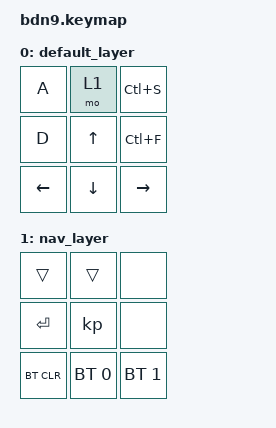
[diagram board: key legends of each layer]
#include <behaviors.dtsi>
#include <dt-bindings/zmk/bt.h>
#include <dt-bindings/zmk/keys.h>
#include <dt-bindings/zmk/outputs.h>
#include <dt-bindings/zmk/ext_power.h>

/ {
    keymap {
        compatible = "zmk,keymap";
        
        default_layer {

            bindings = <
    &kp A &mo 1  &kp LC(S)
    &kp D &kp UP  &kp LC(F)
    &kp LEFT &kp DOWN &kp RIGHT
            >;

            sensor-bindings = <&inc_dec_kp C_VOL_UP C_VOL_DN>;
        };

         nav_layer {

             bindings = <
     &trans     &trans         &none
     &kp ENTER  &kp           &none
     &bt BT_CLR &bt BT_SEL 0   &bt BT_SEL 1
             >;

             sensor-bindings = <&inc_dec_kp C_NEXT C_PREV>;
         };
    };
};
